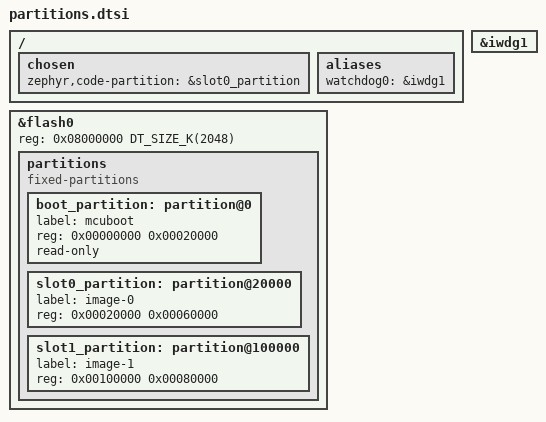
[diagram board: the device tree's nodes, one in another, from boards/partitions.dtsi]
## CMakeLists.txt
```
cmake_minimum_required(VERSION 3.20.0)
find_package(Zephyr REQUIRED HINTS $ENV{ZEPHYR_BASE})
project(rov_mcu)
target_sources(app PRIVATE src/main.c)
target_sources_ifdef(CONFIG_BOOTLOADER_MCUBOOT app PRIVATE src/ota.c)
```

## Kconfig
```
mainmenu "ROV blinky"

config ROV_OTA_CONFIRM
	bool "Confirm a trial image after healthy startup"
	default y
	depends on BOOTLOADER_MCUBOOT
	help
	  Disable only to deliberately exercise trial boot rollback.

source "Kconfig.zephyr"
```

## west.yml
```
manifest:
  version: "1.2"
  projects:
    - name: zephyr
      url: https://github.com/zephyrproject-rtos/zephyr
      revision: v4.2.0
      clone-depth: 1
      import:
        name-allowlist:
          - cmsis
          - cmsis_6
          - hal_stm32
          - mcuboot
          - mbedtls
          - zcbor
  self:
    path: manifest
```

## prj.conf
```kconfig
CONFIG_GPIO=y
CONFIG_LOG=y
CONFIG_MAIN_STACK_SIZE=2048
```

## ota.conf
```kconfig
CONFIG_NETWORKING=y
CONFIG_NET_IPV4=y
CONFIG_NET_IPV6=n
CONFIG_NET_UDP=y
CONFIG_NET_SOCKETS=y
CONFIG_NET_L2_ETHERNET=y
CONFIG_ETH_STM32_HAL=y
CONFIG_NET_CONFIG_SETTINGS=y
CONFIG_NET_CONFIG_AUTO_INIT=n
CONFIG_NET_CONFIG_MY_IPV4_ADDR="10.77.0.2"
CONFIG_NET_CONFIG_MY_IPV4_NETMASK="255.255.255.0"
CONFIG_NET_CONFIG_MY_IPV4_GW="0.0.0.0"
CONFIG_NET_PKT_RX_COUNT=16
CONFIG_NET_PKT_TX_COUNT=16
CONFIG_NET_BUF_RX_COUNT=24
CONFIG_NET_BUF_TX_COUNT=24

CONFIG_ZCBOR=y
CONFIG_CRC=y
CONFIG_FLASH=y
CONFIG_FLASH_MAP=y
CONFIG_STREAM_FLASH=y
CONFIG_IMG_MANAGER=y
CONFIG_MCUMGR=y
CONFIG_MCUMGR_GRP_IMG=y
CONFIG_MCUMGR_GRP_IMG_SLOT_INFO=y
CONFIG_MCUMGR_GRP_IMG_VERBOSE_ERR=y
CONFIG_MCUMGR_GRP_IMG_TOO_LARGE_SYSBUILD=y
CONFIG_MCUMGR_GRP_OS=y
CONFIG_MCUMGR_TRANSPORT_UDP=y
CONFIG_MCUMGR_TRANSPORT_UDP_IPV4=y
CONFIG_MCUMGR_TRANSPORT_UDP_IPV6=n
CONFIG_MCUMGR_TRANSPORT_UDP_PORT=1337
CONFIG_MCUMGR_TRANSPORT_UDP_AUTOMATIC_INIT=n
CONFIG_SYSTEM_WORKQUEUE_STACK_SIZE=3072
CONFIG_MAIN_STACK_SIZE=4096
CONFIG_REBOOT=y
CONFIG_WATCHDOG=y
CONFIG_WDT_DISABLE_AT_BOOT=n
CONFIG_IWDG_STM32_INITIAL_TIMEOUT=8000
```

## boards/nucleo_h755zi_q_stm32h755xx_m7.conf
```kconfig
# ST-LINK virtual COM port, 115200 baud (USART3 PD8/PD9).
CONFIG_SERIAL=y
CONFIG_CONSOLE=y
CONFIG_UART_CONSOLE=y
```

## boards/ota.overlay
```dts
#include "partitions.dtsi"
```

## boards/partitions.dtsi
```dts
/* STM32H755: 128 KiB erase sectors; same offset-swap geometry as K2. */
/ {
	chosen { zephyr,code-partition = &slot0_partition; };
	aliases { watchdog0 = &iwdg1; };
};

&flash0 {
	reg = <0x08000000 DT_SIZE_K(2048)>;
	#address-cells = <1>;
	#size-cells = <1>;
	ranges = <0 0x08000000 DT_SIZE_K(2048)>;
	partitions {
		compatible = "fixed-partitions";
		#address-cells = <1>;
		#size-cells = <1>;
		boot_partition: partition@0 {
			label = "mcuboot";
			reg = <0x00000000 0x00020000>;
			read-only;
		};
		slot0_partition: partition@20000 {
			label = "image-0";
			reg = <0x00020000 0x00060000>;
		};
		slot1_partition: partition@100000 {
			label = "image-1";
			reg = <0x00100000 0x00080000>;
		};
	};
};

&iwdg1 { status = "okay"; };
```

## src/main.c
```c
#include <app_version.h>
#include <zephyr/drivers/gpio.h>
#include <zephyr/kernel.h>
#include <zephyr/logging/log.h>

#include "ota.h"

LOG_MODULE_REGISTER(blinky, LOG_LEVEL_INF);

static const struct gpio_dt_spec led = GPIO_DT_SPEC_GET(DT_ALIAS(led0), gpios);

int main(void)
{
	if (!gpio_is_ready_dt(&led)) {
		LOG_ERR("LED device is not ready");
		return 0;
	}

	int ret = gpio_pin_configure_dt(&led, GPIO_OUTPUT_INACTIVE);

	if (ret < 0) {
		LOG_ERR("LED configuration failed: %d", ret);
		return 0;
	}

	ret = ota_init();
	if (ret < 0) {
		LOG_ERR("OTA startup failed: %d", ret);
		return 0;
	}

	LOG_INF("ROV blinky %s on %s", APP_VERSION_STRING, CONFIG_BOARD_TARGET);
	while (true) {
		ret = gpio_pin_toggle_dt(&led);
		if (ret < 0) {
			LOG_ERR("LED toggle failed: %d", ret);
			return 0;
		}
		ota_tick();
		k_sleep(K_MSEC(500));
	}
	return 0;
}
```

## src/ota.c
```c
#include <zephyr/dfu/mcuboot.h>
#include <zephyr/drivers/watchdog.h>
#include <zephyr/kernel.h>
#include <zephyr/logging/log.h>
#include <zephyr/mgmt/mcumgr/transport/smp_udp.h>
#include <zephyr/net/net_config.h>
#include <zephyr/net/net_if.h>
#include <zephyr/sys/reboot.h>

#include "ota.h"
#include "ota_policy.h"

LOG_MODULE_REGISTER(ota, LOG_LEVEL_INF);

static const struct device *const watchdog = DEVICE_DT_GET(DT_ALIAS(watchdog0));
static struct ota_policy policy;

int ota_init(void)
{
	/* MCUboot starts IWDG and feeds it during swaps; the app driver restarts
	 * its 8 s timeout during init. Only the successful main loop feeds it. */
	if (!device_is_ready(watchdog)) {
		return -ENODEV;
	}
	policy = (struct ota_policy) {
		.start_ms = k_uptime_get(), .ready_since_ms = -1,
	};
	int ret = net_config_init("ROV Ethernet OTA", NET_CONFIG_NEED_IPV4, 0);

	if (ret < 0) {
		return ret;
	}
	ret = smp_udp_open();
	if (ret < 0) {
		return ret;
	}
	LOG_INF("MCUmgr on %s:1337; confirmed=%d",
		CONFIG_NET_CONFIG_MY_IPV4_ADDR, boot_is_img_confirmed());
	return 0;
}

void ota_tick(void)
{
	struct net_if *iface = net_if_get_default();
	bool healthy = iface != NULL && net_if_is_up(iface) &&
		       net_if_is_carrier_ok(iface) &&
		       net_if_ipv4_get_global_addr(iface, NET_ADDR_PREFERRED) != NULL;
	enum ota_action action = ota_policy_step(&policy, k_uptime_get(),
		boot_is_img_confirmed(), healthy, IS_ENABLED(CONFIG_ROV_OTA_CONFIRM));

	if (action == OTA_REVERT) {
		LOG_ERR("Trial image did not become healthy; resetting for rollback");
		sys_reboot(SYS_REBOOT_COLD);
	} else if (action == OTA_CONFIRM) {
		int ret = boot_write_img_confirmed();

		if (ret < 0) {
			LOG_ERR("Image confirmation failed: %d", ret);
		} else {
			LOG_INF("Image confirmed after healthy startup and Ethernet link");
		}
	}
	wdt_feed(watchdog, 0);
}
```

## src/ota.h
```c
#ifndef ROV_OTA_H
#define ROV_OTA_H

#if defined(CONFIG_BOOTLOADER_MCUBOOT)
int ota_init(void);
void ota_tick(void);
#else
static inline int ota_init(void) { return 0; }
static inline void ota_tick(void) {}
#endif
#endif
```

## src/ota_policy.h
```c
#ifndef ROV_OTA_POLICY_H
#define ROV_OTA_POLICY_H

#include <stdbool.h>
#include <stdint.h>

#define OTA_HEALTH_MS 5000
#define OTA_TRIAL_MS 60000

enum ota_action { OTA_WAIT, OTA_CONFIRM, OTA_REVERT };

struct ota_policy {
	int64_t start_ms;
	int64_t ready_since_ms;
};

static inline enum ota_action ota_policy_step(struct ota_policy *policy,
		int64_t now, bool confirmed, bool healthy, bool allow_confirm)
{
	if (confirmed) {
		return OTA_WAIT;
	}
	if (now - policy->start_ms >= OTA_TRIAL_MS) {
		return OTA_REVERT;
	}
	if (!healthy) {
		policy->ready_since_ms = -1;
	} else if (policy->ready_since_ms < 0) {
		policy->ready_since_ms = now;
	} else if (allow_confirm && now - policy->ready_since_ms >= OTA_HEALTH_MS) {
		return OTA_CONFIRM;
	}
	return OTA_WAIT;
}
#endif
```
